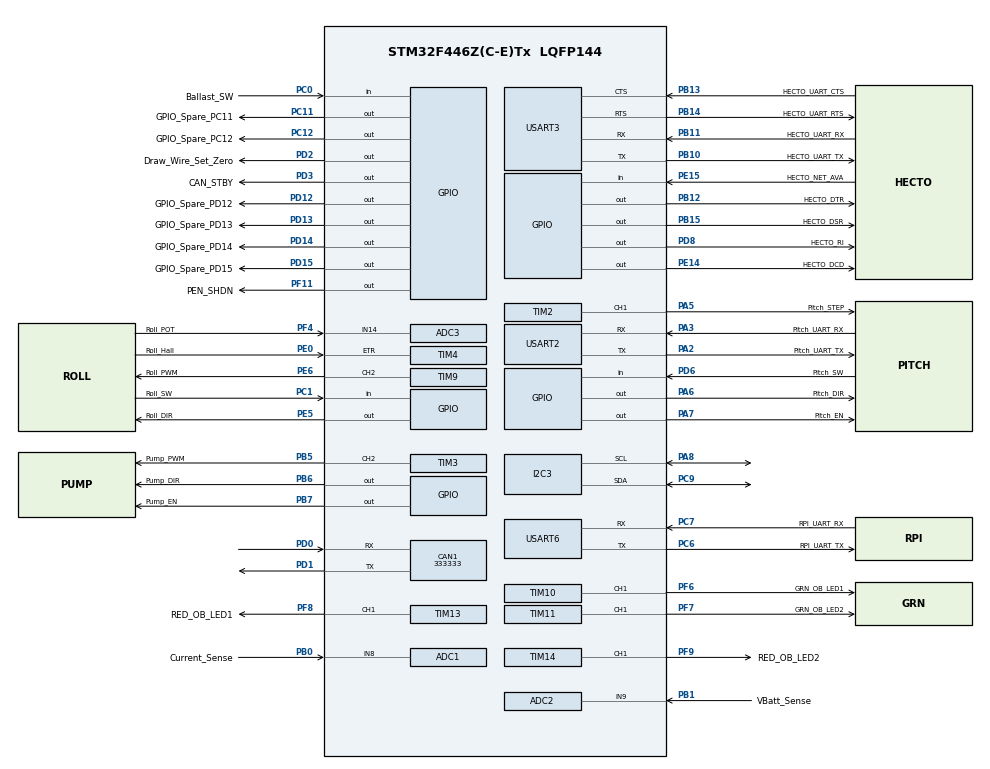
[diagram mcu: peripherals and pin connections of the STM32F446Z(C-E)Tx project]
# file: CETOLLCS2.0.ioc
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ADC1.Channel-0\#ChannelRegularConversion=ADC_CHANNEL_8
ADC1.NbrOfConversionFlag=1
ADC1.Rank-0\#ChannelRegularConversion=1
ADC1.SamplingTime-0\#ChannelRegularConversion=ADC_SAMPLETIME_3CYCLES
ADC1.master=1
ADC2.Channel-0\#ChannelRegularConversion=ADC_CHANNEL_9
ADC2.NbrOfConversionFlag=1
ADC2.Rank-0\#ChannelRegularConversion=1
ADC2.SamplingTime-0\#ChannelRegularConversion=ADC_SAMPLETIME_3CYCLES
ADC3.Channel-0\#ChannelRegularConversion=ADC_CHANNEL_14
ADC3.ContinuousConvMode=ENABLE
ADC3.DMAContinuousRequests=ENABLE
ADC3.NbrOfConversionFlag=1
ADC3.Rank-0\#ChannelRegularConversion=1
ADC3.SamplingTime-0\#ChannelRegularConversion=ADC_SAMPLETIME_3CYCLES
CAN1.CalculateBaudRate=333333
CAN1.CalculateTimeBit=3000
CAN1.CalculateTimeQuantum=1000.0
Dma.ADC3.0.Direction=DMA_PERIPH_TO_MEMORY
Dma.ADC3.0.FIFOMode=DMA_FIFOMODE_DISABLE
Dma.ADC3.0.Instance=DMA2_Stream0
Dma.ADC3.0.MemDataAlignment=DMA_MDATAALIGN_HALFWORD
Dma.ADC3.0.MemInc=DMA_MINC_DISABLE
Dma.ADC3.0.Mode=DMA_CIRCULAR
Dma.ADC3.0.PeriphDataAlignment=DMA_PDATAALIGN_HALFWORD
Dma.ADC3.0.PeriphInc=DMA_PINC_DISABLE
Dma.ADC3.0.Priority=DMA_PRIORITY_LOW
Dma.Request0=ADC3
FREERTOS.Tasks01=defaultTask,0,128,StartDefaultTask,Default,NULL,Dynamic,NULL,NULL
Mcu.Family=STM32F4
Mcu.Name=STM32F446Z(C-E)Tx
Mcu.Package=LQFP144
NVIC.DMA2_Stream0_IRQn=true\:5\:0\:false\:false\:true\:true\:false\:true\:true
NVIC.PriorityGroup=NVIC_PRIORITYGROUP_4
NVIC.TIM1_UP_TIM10_IRQn=true\:15\:0\:false\:false\:true\:false\:false\:true\:true
NVIC.TIM2_IRQn=true\:5\:0\:false\:false\:true\:true\:true\:true\:true
NVIC.TimeBase=TIM1_UP_TIM10_IRQn
NVIC.TimeBaseIP=TIM1
PA13.Mode=Serial_Wire
PA13.Signal=SYS_JTMS-SWDIO
PA14.Mode=Serial_Wire
PA14.Signal=SYS_JTCK-SWCLK
PA2.GPIO_Label=Pitch_UART_TX
PA2.Mode=Asynchronous
PA2.Signal=USART2_TX
PA3.GPIO_Label=Pitch_UART_RX
PA3.Mode=Asynchronous
PA3.Signal=USART2_RX
PA5.GPIO_Label=Pitch_STEP
PA5.Signal=S_TIM2_CH1_ETR
PA6.GPIO_Label=Pitch_DIR
PA6.Signal=GPIO_Output
PA7.GPIO_Label=Pitch_EN
PA7.Signal=GPIO_Output
PA8.Mode=I2C
PA8.Signal=I2C3_SCL
PB0.GPIO_Label=Current_Sense
PB0.Signal=ADCx_IN8
PB1.GPIO_Label=VBatt_Sense
PB1.Signal=ADCx_IN9
PB10.GPIO_Label=HECTO_UART_TX
PB10.Mode=Asynchronous
PB10.Signal=USART3_TX
PB11.GPIO_Label=HECTO_UART_RX
PB11.Mode=Asynchronous
PB11.Signal=USART3_RX
PB12.GPIO_Label=HECTO_DTR
PB12.Signal=GPIO_Output
PB13.GPIO_Label=HECTO_UART_CTS
PB13.Mode=CTS_RTS
PB13.Signal=USART3_CTS
PB14.GPIO_Label=HECTO_UART_RTS
PB14.Mode=CTS_RTS
PB14.Signal=USART3_RTS
PB15.GPIO_Label=HECTO_DSR
PB15.Signal=GPIO_Output
PB3.Signal=SYS_JTDO-SWO
PB5.GPIO_Label=Pump_PWM
PB5.Signal=S_TIM3_CH2
PB6.GPIO_Label=Pump_DIR
PB6.Signal=GPIO_Output
PB7.GPIO_Label=Pump_EN
PB7.Signal=GPIO_Output
PC0.GPIO_Label=Ballast_SW
PC0.Signal=GPIO_Input
PC1.GPIO_Label=Roll_SW
PC1.Signal=GPIO_Input
PC11.GPIO_Label=GPIO_Spare_PC11
PC11.Signal=GPIO_Output
PC12.GPIO_Label=GPIO_Spare_PC12
PC12.Signal=GPIO_Output
PC6.GPIO_Label=RPI_UART_TX
PC6.Mode=Asynchronous
PC6.Signal=USART6_TX
PC7.GPIO_Label=RPI_UART_RX
PC7.Mode=Asynchronous
PC7.Signal=USART6_RX
PC9.Mode=I2C
PC9.Signal=I2C3_SDA
PD0.Mode=CAN_Activate
PD0.Signal=CAN1_RX
PD1.Mode=CAN_Activate
PD1.Signal=CAN1_TX
PD12.GPIO_Label=GPIO_Spare_PD12
PD12.Signal=GPIO_Output
PD13.GPIO_Label=GPIO_Spare_PD13
PD13.Signal=GPIO_Output
PD14.GPIO_Label=GPIO_Spare_PD14
PD14.Signal=GPIO_Output
PD15.GPIO_Label=GPIO_Spare_PD15
PD15.Signal=GPIO_Output
PD2.GPIO_Label=Draw_Wire_Set_Zero
PD2.Signal=GPIO_Output
PD3.GPIO_Label=CAN_STBY
PD3.Signal=GPIO_Output
PD6.GPIO_Label=Pitch_SW
PD6.GPIO_PuPd=GPIO_PULLUP
PD6.Signal=GPIO_Input
PD8.GPIO_Label=HECTO_RI
PD8.Signal=GPIO_Output
PE0.GPIO_Label=Roll_Hall
PE0.Signal=S_TIM4_ETR
PE14.GPIO_Label=HECTO_DCD
PE14.Signal=GPIO_Output
PE15.GPIO_Label=HECTO_NET_AVA
PE15.Signal=GPIO_Input
PE5.GPIO_Label=Roll_DIR
PE5.Signal=GPIO_Output
PE6.GPIO_Label=Roll_PWM
PE6.Signal=S_TIM9_CH2
PF11.GPIO_Label=PEN_SHDN
PF11.Signal=GPIO_Output
PF4.GPIO_Label=Roll_POT
PF4.Mode=IN14
PF4.Signal=ADC3_IN14
PF6.GPIO_Label=GRN_OB_LED1
PF6.Signal=S_TIM10_CH1
PF7.GPIO_Label=GRN_OB_LED2
PF7.Signal=S_TIM11_CH1
PF8.GPIO_Label=RED_OB_LED1
PF8.Signal=S_TIM13_CH1
PF9.GPIO_Label=RED_OB_LED2
PF9.Signal=S_TIM14_CH1
PH0-OSC_IN.Mode=HSE-External-Oscillator
PH0-OSC_IN.Signal=RCC_OSC_IN
PH1-OSC_OUT.Mode=HSE-External-Oscillator
PH1-OSC_OUT.Signal=RCC_OSC_OUT
ProjectManager.HeapSize=0x200
ProjectManager.StackSize=0x400
ProjectManager.TargetToolchain=STM32CubeIDE
RCC.CortexFreq_Value=16000000
RCC.HSE_VALUE=16000000
RCC.PLLSourceVirtual=RCC_PLLSOURCE_HSE
RCC.SYSCLKSource=RCC_SYSCLKSOURCE_HSE
RCC.USBFreq_Value=96000000
RCC.VCOOutputFreq_Value=192000000
SH.ADCx_IN8.0=ADC1_IN8,IN8
SH.ADCx_IN9.0=ADC2_IN9,IN9
SH.S_TIM10_CH1.0=TIM10_CH1,PWM Generation1 CH1
SH.S_TIM11_CH1.0=TIM11_CH1,PWM Generation1 CH1
SH.S_TIM13_CH1.0=TIM13_CH1,PWM Generation1 CH1
SH.S_TIM14_CH1.0=TIM14_CH1,PWM Generation1 CH1
SH.S_TIM2_CH1_ETR.0=TIM2_CH1,PWM Generation1 CH1
SH.S_TIM3_CH2.0=TIM3_CH2,PWM Generation2 CH2
SH.S_TIM4_ETR.0=TIM4_ETR,ClockSourceETR_Mode2
SH.S_TIM9_CH2.0=TIM9_CH2,PWM Generation2 CH2
TIM10.Channel=TIM_CHANNEL_1
TIM11.Channel=TIM_CHANNEL_1
TIM13.Channel=TIM_CHANNEL_1
TIM14.Channel=TIM_CHANNEL_1
TIM2.AutoReloadPreload=TIM_AUTORELOAD_PRELOAD_ENABLE
TIM2.Channel-PWM\ Generation1\ CH1=TIM_CHANNEL_1
TIM2.Period=6000
TIM3.Channel-PWM\ Generation2\ CH2=TIM_CHANNEL_2
TIM9.Channel-PWM\ Generation2\ CH2=TIM_CHANNEL_2
USART2.VirtualMode=VM_ASYNC
USART3.VirtualMode=VM_ASYNC
USART6.VirtualMode=VM_ASYNC
VP_FREERTOS_VS_CMSIS_V1.Mode=CMSIS_V1
VP_SYS_VS_tim1.Mode=TIM1
VP_TIM10_VS_ClockSourceINT.Mode=Enable_Timer
VP_TIM11_VS_ClockSourceINT.Mode=Enable_Timer
VP_TIM13_VS_ClockSourceINT.Mode=Enable_Timer
VP_TIM14_VS_ClockSourceINT.Mode=Enable_Timer
board=custom

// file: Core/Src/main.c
/* USER CODE BEGIN Header */
/**
  ******************************************************************************
  * @file           : main.c
  * @brief          : Main program body
  ******************************************************************************
  * @attention
  *
  * Copyright (c) 2026 STMicroelectronics.
  * All rights reserved.
  *
  * This software is licensed under terms that can be found in the LICENSE file
  * in the root directory of this software component.
  * If no LICENSE file comes with this software, it is provided AS-IS.
  *
  ******************************************************************************
  */
/* USER CODE END Header */
#include "main.h"
#include "cmsis_os.h"

/* USER CODE BEGIN Includes */
#include "pitch_motor.h"

/* USER CODE END Includes */

ADC_HandleTypeDef hadc1;
ADC_HandleTypeDef hadc2;
ADC_HandleTypeDef hadc3;
DMA_HandleTypeDef hdma_adc3;

CAN_HandleTypeDef hcan1;

I2C_HandleTypeDef hi2c3;

TIM_HandleTypeDef htim2;
TIM_HandleTypeDef htim3;
TIM_HandleTypeDef htim4;
TIM_HandleTypeDef htim9;
TIM_HandleTypeDef htim10;
TIM_HandleTypeDef htim11;
TIM_HandleTypeDef htim13;
TIM_HandleTypeDef htim14;

UART_HandleTypeDef huart2;
UART_HandleTypeDef huart3;
UART_HandleTypeDef huart6;

osThreadId defaultTaskHandle;

void SystemClock_Config(void);
static void MX_GPIO_Init(void);
static void MX_DMA_Init(void);
static void MX_ADC1_Init(void);
static void MX_ADC2_Init(void);
static void MX_ADC3_Init(void);
static void MX_CAN1_Init(void);
static void MX_I2C3_Init(void);
static void MX_TIM2_Init(void);
static void MX_TIM3_Init(void);
static void MX_TIM4_Init(void);
static void MX_TIM9_Init(void);
static void MX_TIM10_Init(void);
static void MX_TIM11_Init(void);
static void MX_TIM13_Init(void);
static void MX_TIM14_Init(void);
static void MX_USART2_UART_Init(void);
static void MX_USART3_UART_Init(void);
static void MX_USART6_UART_Init(void);
void StartDefaultTask(void const * argument);

int main(void)
{

  /* MCU Configuration--------------------------------------------------------*/

  /* Reset of all peripherals, Initializes the Flash interface and the Systick. */
  HAL_Init();

  /* Configure the system clock */
  SystemClock_Config();

  /* Initialize all configured peripherals */
  MX_GPIO_Init();
  MX_DMA_Init();
  MX_ADC1_Init();
  MX_ADC2_Init();
  MX_ADC3_Init();
  MX_CAN1_Init();
  MX_I2C3_Init();
  MX_TIM2_Init();
  MX_TIM3_Init();
  MX_TIM4_Init();
  MX_TIM9_Init();
  MX_TIM10_Init();
  MX_TIM11_Init();
  MX_TIM13_Init();
  MX_TIM14_Init();
  MX_USART2_UART_Init();
  MX_USART3_UART_Init();
  MX_USART6_UART_Init();
  /* USER CODE BEGIN 2 */
  pitch_init_motor();
  HAL_Delay(50);

  while(1){
	  HAL_Delay(10);
	  pitch_move_to(90);

	  HAL_Delay(5);
	  pitch_move_to(10);
	  HAL_Delay(5);
  }
  /* USER CODE END 2 */

  /* Create the thread(s) */
  /* definition and creation of defaultTask */
  osThreadDef(defaultTask, StartDefaultTask, osPriorityNormal, 0, 128);
  defaultTaskHandle = osThreadCreate(osThread(defaultTask), NULL);

  /* Start scheduler */
  osKernelStart();

  /* We should never get here as control is now taken by the scheduler */

  /* Infinite loop */
  while (1)
  {

  }
}

void SystemClock_Config(void)
{
  RCC_OscInitTypeDef RCC_OscInitStruct = {0};
  RCC_ClkInitTypeDef RCC_ClkInitStruct = {0};

  /** Configure the main internal regulator output voltage
  */
  __HAL_RCC_PWR_CLK_ENABLE();
  __HAL_PWR_VOLTAGESCALING_CONFIG(PWR_REGULATOR_VOLTAGE_SCALE3);

  /** Initializes the RCC Oscillators according to the specified parameters
  * in the RCC_OscInitTypeDef structure.
  */
  RCC_OscInitStruct.OscillatorType = RCC_OSCILLATORTYPE_HSE;
  RCC_OscInitStruct.HSEState = RCC_HSE_ON;
  RCC_OscInitStruct.PLL.PLLState = RCC_PLL_NONE;
  if (HAL_RCC_OscConfig(&RCC_OscInitStruct) != HAL_OK)
  {
    Error_Handler();
  }

  /** Initializes the CPU, AHB and APB buses clocks
  */
  RCC_ClkInitStruct.ClockType = RCC_CLOCKTYPE_HCLK|RCC_CLOCKTYPE_SYSCLK
                              |RCC_CLOCKTYPE_PCLK1|RCC_CLOCKTYPE_PCLK2;
  RCC_ClkInitStruct.SYSCLKSource = RCC_SYSCLKSOURCE_HSE;
  RCC_ClkInitStruct.AHBCLKDivider = RCC_SYSCLK_DIV1;
  RCC_ClkInitStruct.APB1CLKDivider = RCC_HCLK_DIV1;
  RCC_ClkInitStruct.APB2CLKDivider = RCC_HCLK_DIV1;

  if (HAL_RCC_ClockConfig(&RCC_ClkInitStruct, FLASH_LATENCY_0) != HAL_OK)
  {
    Error_Handler();
  }
}

static void MX_ADC1_Init(void)
{

  ADC_ChannelConfTypeDef sConfig = {0};

  /** Configure the global features of the ADC (Clock, Resolution, Data Alignment and number of conversion)
  */
  hadc1.Instance = ADC1;
  hadc1.Init.ClockPrescaler = ADC_CLOCK_SYNC_PCLK_DIV2;
  hadc1.Init.Resolution = ADC_RESOLUTION_12B;
  hadc1.Init.ScanConvMode = DISABLE;
  hadc1.Init.ContinuousConvMode = DISABLE;
  hadc1.Init.DiscontinuousConvMode = DISABLE;
  hadc1.Init.ExternalTrigConvEdge = ADC_EXTERNALTRIGCONVEDGE_NONE;
  hadc1.Init.ExternalTrigConv = ADC_SOFTWARE_START;
  hadc1.Init.DataAlign = ADC_DATAALIGN_RIGHT;
  hadc1.Init.NbrOfConversion = 1;
  hadc1.Init.DMAContinuousRequests = DISABLE;
  hadc1.Init.EOCSelection = ADC_EOC_SINGLE_CONV;
  if (HAL_ADC_Init(&hadc1) != HAL_OK)
  {
    Error_Handler();
  }

  /** Configure for the selected ADC regular channel its corresponding rank in the sequencer and its sample time.
  */
  sConfig.Channel = ADC_CHANNEL_8;
  sConfig.Rank = 1;
  sConfig.SamplingTime = ADC_SAMPLETIME_3CYCLES;
  if (HAL_ADC_ConfigChannel(&hadc1, &sConfig) != HAL_OK)
  {
    Error_Handler();
  }

}

static void MX_ADC2_Init(void)
{

  ADC_ChannelConfTypeDef sConfig = {0};

  /** Configure the global features of the ADC (Clock, Resolution, Data Alignment and number of conversion)
  */
  hadc2.Instance = ADC2;
  hadc2.Init.ClockPrescaler = ADC_CLOCK_SYNC_PCLK_DIV2;
  hadc2.Init.Resolution = ADC_RESOLUTION_12B;
  hadc2.Init.ScanConvMode = DISABLE;
  hadc2.Init.ContinuousConvMode = DISABLE;
  hadc2.Init.DiscontinuousConvMode = DISABLE;
  hadc2.Init.ExternalTrigConvEdge = ADC_EXTERNALTRIGCONVEDGE_NONE;
  hadc2.Init.ExternalTrigConv = ADC_SOFTWARE_START;
  hadc2.Init.DataAlign = ADC_DATAALIGN_RIGHT;
  hadc2.Init.NbrOfConversion = 1;
  hadc2.Init.DMAContinuousRequests = DISABLE;
  hadc2.Init.EOCSelection = ADC_EOC_SINGLE_CONV;
  if (HAL_ADC_Init(&hadc2) != HAL_OK)
  {
    Error_Handler();
  }

  /** Configure for the selected ADC regular channel its corresponding rank in the sequencer and its sample time.
  */
  sConfig.Channel = ADC_CHANNEL_9;
  sConfig.Rank = 1;
  sConfig.SamplingTime = ADC_SAMPLETIME_3CYCLES;
  if (HAL_ADC_ConfigChannel(&hadc2, &sConfig) != HAL_OK)
  {
    Error_Handler();
  }

}

static void MX_ADC3_Init(void)
{

  ADC_ChannelConfTypeDef sConfig = {0};

  /** Configure the global features of the ADC (Clock, Resolution, Data Alignment and number of conversion)
  */
  hadc3.Instance = ADC3;
  hadc3.Init.ClockPrescaler = ADC_CLOCK_SYNC_PCLK_DIV2;
  hadc3.Init.Resolution = ADC_RESOLUTION_12B;
  hadc3.Init.ScanConvMode = DISABLE;
  hadc3.Init.ContinuousConvMode = ENABLE;
  hadc3.Init.DiscontinuousConvMode = DISABLE;
  hadc3.Init.ExternalTrigConvEdge = ADC_EXTERNALTRIGCONVEDGE_NONE;
  hadc3.Init.ExternalTrigConv = ADC_SOFTWARE_START;
  hadc3.Init.DataAlign = ADC_DATAALIGN_RIGHT;
  hadc3.Init.NbrOfConversion = 1;
  hadc3.Init.DMAContinuousRequests = ENABLE;
  hadc3.Init.EOCSelection = ADC_EOC_SINGLE_CONV;
  if (HAL_ADC_Init(&hadc3) != HAL_OK)
  {
    Error_Handler();
  }

  /** Configure for the selected ADC regular channel its corresponding rank in the sequencer and its sample time.
  */
  sConfig.Channel = ADC_CHANNEL_14;
  sConfig.Rank = 1;
  sConfig.SamplingTime = ADC_SAMPLETIME_3CYCLES;
  if (HAL_ADC_ConfigChannel(&hadc3, &sConfig) != HAL_OK)
  {
    Error_Handler();
  }

}

static void MX_CAN1_Init(void)
{

  hcan1.Instance = CAN1;
  hcan1.Init.Prescaler = 16;
  hcan1.Init.Mode = CAN_MODE_NORMAL;
  hcan1.Init.SyncJumpWidth = CAN_SJW_1TQ;
  hcan1.Init.TimeSeg1 = CAN_BS1_1TQ;
  hcan1.Init.TimeSeg2 = CAN_BS2_1TQ;
  hcan1.Init.TimeTriggeredMode = DISABLE;
  hcan1.Init.AutoBusOff = DISABLE;
  hcan1.Init.AutoWakeUp = DISABLE;
  hcan1.Init.AutoRetransmission = DISABLE;
  hcan1.Init.ReceiveFifoLocked = DISABLE;
  hcan1.Init.TransmitFifoPriority = DISABLE;
  if (HAL_CAN_Init(&hcan1) != HAL_OK)
  {
    Error_Handler();
  }

}

static void MX_I2C3_Init(void)
{

  hi2c3.Instance = I2C3;
  hi2c3.Init.ClockSpeed = 100000;
  hi2c3.Init.DutyCycle = I2C_DUTYCYCLE_2;
  hi2c3.Init.OwnAddress1 = 0;
  hi2c3.Init.AddressingMode = I2C_ADDRESSINGMODE_7BIT;
  hi2c3.Init.DualAddressMode = I2C_DUALADDRESS_DISABLE;
  hi2c3.Init.OwnAddress2 = 0;
  hi2c3.Init.GeneralCallMode = I2C_GENERALCALL_DISABLE;
  hi2c3.Init.NoStretchMode = I2C_NOSTRETCH_DISABLE;
  if (HAL_I2C_Init(&hi2c3) != HAL_OK)
  {
    Error_Handler();
  }

}

static void MX_TIM2_Init(void)
{

  TIM_MasterConfigTypeDef sMasterConfig = {0};
  TIM_OC_InitTypeDef sConfigOC = {0};

  htim2.Instance = TIM2;
  htim2.Init.Prescaler = 0;
  htim2.Init.CounterMode = TIM_COUNTERMODE_UP;
  htim2.Init.Period = 6000;
  htim2.Init.ClockDivision = TIM_CLOCKDIVISION_DIV1;
  htim2.Init.AutoReloadPreload = TIM_AUTORELOAD_PRELOAD_ENABLE;
  if (HAL_TIM_PWM_Init(&htim2) != HAL_OK)
  {
    Error_Handler();
  }
  sMasterConfig.MasterOutputTrigger = TIM_TRGO_RESET;
  sMasterConfig.MasterSlaveMode = TIM_MASTERSLAVEMODE_DISABLE;
  if (HAL_TIMEx_MasterConfigSynchronization(&htim2, &sMasterConfig) != HAL_OK)
  {
    Error_Handler();
  }
  sConfigOC.OCMode = TIM_OCMODE_PWM1;
  sConfigOC.Pulse = 0;
  sConfigOC.OCPolarity = TIM_OCPOLARITY_HIGH;
  sConfigOC.OCFastMode = TIM_OCFAST_DISABLE;
  if (HAL_TIM_PWM_ConfigChannel(&htim2, &sConfigOC, TIM_CHANNEL_1) != HAL_OK)
  {
    Error_Handler();
  }
  HAL_TIM_MspPostInit(&htim2);

}

static void MX_TIM3_Init(void)
{

  TIM_MasterConfigTypeDef sMasterConfig = {0};
  TIM_OC_InitTypeDef sConfigOC = {0};

  htim3.Instance = TIM3;
  htim3.Init.Prescaler = 0;
  htim3.Init.CounterMode = TIM_COUNTERMODE_UP;
  htim3.Init.Period = 65535;
  htim3.Init.ClockDivision = TIM_CLOCKDIVISION_DIV1;
  htim3.Init.AutoReloadPreload = TIM_AUTORELOAD_PRELOAD_DISABLE;
  if (HAL_TIM_PWM_Init(&htim3) != HAL_OK)
  {
    Error_Handler();
  }
  sMasterConfig.MasterOutputTrigger = TIM_TRGO_RESET;
  sMasterConfig.MasterSlaveMode = TIM_MASTERSLAVEMODE_DISABLE;
  if (HAL_TIMEx_MasterConfigSynchronization(&htim3, &sMasterConfig) != HAL_OK)
  {
    Error_Handler();
  }
  sConfigOC.OCMode = TIM_OCMODE_PWM1;
  sConfigOC.Pulse = 0;
  sConfigOC.OCPolarity = TIM_OCPOLARITY_HIGH;
  sConfigOC.OCFastMode = TIM_OCFAST_DISABLE;
  if (HAL_TIM_PWM_ConfigChannel(&htim3, &sConfigOC, TIM_CHANNEL_2) != HAL_OK)
  {
    Error_Handler();
  }
  HAL_TIM_MspPostInit(&htim3);

}

static void MX_TIM4_Init(void)
{

  TIM_ClockConfigTypeDef sClockSourceConfig = {0};
  TIM_MasterConfigTypeDef sMasterConfig = {0};

  htim4.Instance = TIM4;
  htim4.Init.Prescaler = 0;
  htim4.Init.CounterMode = TIM_COUNTERMODE_UP;
  htim4.Init.Period = 65535;
  htim4.Init.ClockDivision = TIM_CLOCKDIVISION_DIV1;
  htim4.Init.AutoReloadPreload = TIM_AUTORELOAD_PRELOAD_DISABLE;
  if (HAL_TIM_Base_Init(&htim4) != HAL_OK)
  {
    Error_Handler();
  }
  sClockSourceConfig.ClockSource = TIM_CLOCKSOURCE_ETRMODE2;
  sClockSourceConfig.ClockPolarity = TIM_CLOCKPOLARITY_NONINVERTED;
  sClockSourceConfig.ClockPrescaler = TIM_CLOCKPRESCALER_DIV1;
  sClockSourceConfig.ClockFilter = 0;
  if (HAL_TIM_ConfigClockSource(&htim4, &sClockSourceConfig) != HAL_OK)
  {
    Error_Handler();
  }
  sMasterConfig.MasterOutputTrigger = TIM_TRGO_RESET;
  sMasterConfig.MasterSlaveMode = TIM_MASTERSLAVEMODE_DISABLE;
  if (HAL_TIMEx_MasterConfigSynchronization(&htim4, &sMasterConfig) != HAL_OK)
  {
    Error_Handler();
  }

}

static void MX_TIM9_Init(void)
{

  TIM_OC_InitTypeDef sConfigOC = {0};

  htim9.Instance = TIM9;
  htim9.Init.Prescaler = 0;
  htim9.Init.CounterMode = TIM_COUNTERMODE_UP;
  htim9.Init.Period = 65535;
  htim9.Init.ClockDivision = TIM_CLOCKDIVISION_DIV1;
  htim9.Init.AutoReloadPreload = TIM_AUTORELOAD_PRELOAD_DISABLE;
  if (HAL_TIM_PWM_Init(&htim9) != HAL_OK)
  {
    Error_Handler();
  }
  sConfigOC.OCMode = TIM_OCMODE_PWM1;
  sConfigOC.Pulse = 0;
  sConfigOC.OCPolarity = TIM_OCPOLARITY_HIGH;
  sConfigOC.OCFastMode = TIM_OCFAST_DISABLE;
  if (HAL_TIM_PWM_ConfigChannel(&htim9, &sConfigOC, TIM_CHANNEL_2) != HAL_OK)
  {
    Error_Handler();
  }
  HAL_TIM_MspPostInit(&htim9);

}

static void MX_TIM10_Init(void)
{

  TIM_OC_InitTypeDef sConfigOC = {0};

  htim10.Instance = TIM10;
  htim10.Init.Prescaler = 0;
  htim10.Init.CounterMode = TIM_COUNTERMODE_UP;
  htim10.Init.Period = 65535;
  htim10.Init.ClockDivision = TIM_CLOCKDIVISION_DIV1;
  htim10.Init.AutoReloadPreload = TIM_AUTORELOAD_PRELOAD_DISABLE;
  if (HAL_TIM_Base_Init(&htim10) != HAL_OK)
  {
    Error_Handler();
  }
  if (HAL_TIM_PWM_Init(&htim10) != HAL_OK)
  {
    Error_Handler();
  }
  sConfigOC.OCMode = TIM_OCMODE_PWM1;
  sConfigOC.Pulse = 0;
  sConfigOC.OCPolarity = TIM_OCPOLARITY_HIGH;
  sConfigOC.OCFastMode = TIM_OCFAST_DISABLE;
  if (HAL_TIM_PWM_ConfigChannel(&htim10, &sConfigOC, TIM_CHANNEL_1) != HAL_OK)
  {
    Error_Handler();
  }
  HAL_TIM_MspPostInit(&htim10);

}

static void MX_TIM11_Init(void)
{

  TIM_OC_InitTypeDef sConfigOC = {0};

  htim11.Instance = TIM11;
  htim11.Init.Prescaler = 0;
  htim11.Init.CounterMode = TIM_COUNTERMODE_UP;
  htim11.Init.Period = 65535;
  htim11.Init.ClockDivision = TIM_CLOCKDIVISION_DIV1;
  htim11.Init.AutoReloadPreload = TIM_AUTORELOAD_PRELOAD_DISABLE;
  if (HAL_TIM_Base_Init(&htim11) != HAL_OK)
  {
    Error_Handler();
  }
  if (HAL_TIM_PWM_Init(&htim11) != HAL_OK)
  {
    Error_Handler();
  }
  sConfigOC.OCMode = TIM_OCMODE_PWM1;
  sConfigOC.Pulse = 0;
  sConfigOC.OCPolarity = TIM_OCPOLARITY_HIGH;
  sConfigOC.OCFastMode = TIM_OCFAST_DISABLE;
  if (HAL_TIM_PWM_ConfigChannel(&htim11, &sConfigOC, TIM_CHANNEL_1) != HAL_OK)
  {
    Error_Handler();
  }
  HAL_TIM_MspPostInit(&htim11);

}

static void MX_TIM13_Init(void)
{

  TIM_OC_InitTypeDef sConfigOC = {0};

  htim13.Instance = TIM13;
  htim13.Init.Prescaler = 0;
  htim13.Init.CounterMode = TIM_COUNTERMODE_UP;
  htim13.Init.Period = 65535;
  htim13.Init.ClockDivision = TIM_CLOCKDIVISION_DIV1;
  htim13.Init.AutoReloadPreload = TIM_AUTORELOAD_PRELOAD_DISABLE;
  if (HAL_TIM_Base_Init(&htim13) != HAL_OK)
  {
    Error_Handler();
  }
  if (HAL_TIM_PWM_Init(&htim13) != HAL_OK)
  {
    Error_Handler();
  }
  sConfigOC.OCMode = TIM_OCMODE_PWM1;
  sConfigOC.Pulse = 0;
  sConfigOC.OCPolarity = TIM_OCPOLARITY_HIGH;
  sConfigOC.OCFastMode = TIM_OCFAST_DISABLE;
  if (HAL_TIM_PWM_ConfigChannel(&htim13, &sConfigOC, TIM_CHANNEL_1) != HAL_OK)
  {
    Error_Handler();
  }
  HAL_TIM_MspPostInit(&htim13);

}

static void MX_TIM14_Init(void)
{

  TIM_OC_InitTypeDef sConfigOC = {0};

  htim14.Instance = TIM14;
  htim14.Init.Prescaler = 0;
  htim14.Init.CounterMode = TIM_COUNTERMODE_UP;
  htim14.Init.Period = 65535;
  htim14.Init.ClockDivision = TIM_CLOCKDIVISION_DIV1;
  htim14.Init.AutoReloadPreload = TIM_AUTORELOAD_PRELOAD_DISABLE;
  if (HAL_TIM_Base_Init(&htim14) != HAL_OK)
  {
    Error_Handler();
  }
  if (HAL_TIM_PWM_Init(&htim14) != HAL_OK)
  {
    Error_Handler();
  }
  sConfigOC.OCMode = TIM_OCMODE_PWM1;
  sConfigOC.Pulse = 0;
  sConfigOC.OCPolarity = TIM_OCPOLARITY_HIGH;
  sConfigOC.OCFastMode = TIM_OCFAST_DISABLE;
  if (HAL_TIM_PWM_ConfigChannel(&htim14, &sConfigOC, TIM_CHANNEL_1) != HAL_OK)
  {
    Error_Handler();
  }
  HAL_TIM_MspPostInit(&htim14);

}

static void MX_USART2_UART_Init(void)
{

  huart2.Instance = USART2;
  huart2.Init.BaudRate = 115200;
  huart2.Init.WordLength = UART_WORDLENGTH_8B;
  huart2.Init.StopBits = UART_STOPBITS_1;
  huart2.Init.Parity = UART_PARITY_NONE;
  huart2.Init.Mode = UART_MODE_TX_RX;
  huart2.Init.HwFlowCtl = UART_HWCONTROL_NONE;
  huart2.Init.OverSampling = UART_OVERSAMPLING_16;
  if (HAL_UART_Init(&huart2) != HAL_OK)
  {
    Error_Handler();
  }

}

static void MX_USART3_UART_Init(void)
{

  huart3.Instance = USART3;
  huart3.Init.BaudRate = 115200;
  huart3.Init.WordLength = UART_WORDLENGTH_8B;
  huart3.Init.StopBits = UART_STOPBITS_1;
  huart3.Init.Parity = UART_PARITY_NONE;
  huart3.Init.Mode = UART_MODE_TX_RX;
  huart3.Init.HwFlowCtl = UART_HWCONTROL_RTS_CTS;
  huart3.Init.OverSampling = UART_OVERSAMPLING_16;
  if (HAL_UART_Init(&huart3) != HAL_OK)
  {
    Error_Handler();
  }

}

static void MX_USART6_UART_Init(void)
{

  huart6.Instance = USART6;
  huart6.Init.BaudRate = 115200;
  huart6.Init.WordLength = UART_WORDLENGTH_8B;
  huart6.Init.StopBits = UART_STOPBITS_1;
  huart6.Init.Parity = UART_PARITY_NONE;
  huart6.Init.Mode = UART_MODE_TX_RX;
  huart6.Init.HwFlowCtl = UART_HWCONTROL_NONE;
  huart6.Init.OverSampling = UART_OVERSAMPLING_16;
  if (HAL_UART_Init(&huart6) != HAL_OK)
  {
    Error_Handler();
  }

}

static void MX_DMA_Init(void)
{

  /* DMA controller clock enable */
  __HAL_RCC_DMA2_CLK_ENABLE();

  /* DMA interrupt init */
  /* DMA2_Stream0_IRQn interrupt configuration */
  HAL_NVIC_SetPriority(DMA2_Stream0_IRQn, 5, 0);
  HAL_NVIC_EnableIRQ(DMA2_Stream0_IRQn);

}

static void MX_GPIO_Init(void)
{
  GPIO_InitTypeDef GPIO_InitStruct = {0};

  /* GPIO Ports Clock Enable */
  __HAL_RCC_GPIOE_CLK_ENABLE();
  __HAL_RCC_GPIOC_CLK_ENABLE();
  __HAL_RCC_GPIOF_CLK_ENABLE();
  __HAL_RCC_GPIOH_CLK_ENABLE();
  __HAL_RCC_GPIOA_CLK_ENABLE();
  __HAL_RCC_GPIOB_CLK_ENABLE();
  __HAL_RCC_GPIOG_CLK_ENABLE();
  __HAL_RCC_GPIOD_CLK_ENABLE();

  /*Configure GPIO pin Output Level */
  HAL_GPIO_WritePin(GPIOE, Roll_DIR_Pin|HECTO_DCD_Pin, GPIO_PIN_RESET);

  /*Configure GPIO pin Output Level */
  HAL_GPIO_WritePin(GPIOA, Pitch_DIR_Pin|Pitch_EN_Pin, GPIO_PIN_RESET);

  /*Configure GPIO pin Output Level */
  HAL_GPIO_WritePin(PEN_SHDN_GPIO_Port, PEN_SHDN_Pin, GPIO_PIN_RESET);

  /*Configure GPIO pin Output Level */
  HAL_GPIO_WritePin(GPIOB, HECTO_DTR_Pin|HECTO_DSR_Pin|Pump_DIR_Pin|Pump_EN_Pin, GPIO_PIN_RESET);

  /*Configure GPIO pin Output Level */
  HAL_GPIO_WritePin(GPIOD, HECTO_RI_Pin|GPIO_Spare_PD12_Pin|GPIO_Spare_PD13_Pin|GPIO_Spare_PD14_Pin
                          |GPIO_Spare_PD15_Pin|Draw_Wire_Set_Zero_Pin|CAN_STBY_Pin, GPIO_PIN_RESET);

  /*Configure GPIO pin Output Level */
  HAL_GPIO_WritePin(GPIOC, GPIO_Spare_PC11_Pin|GPIO_Spare_PC12_Pin, GPIO_PIN_RESET);

  /*Configure GPIO pins : PE2 PE3 PE4 PE7
                           PE8 PE9 PE10 PE11
                           PE12 PE13 PE1 */
  GPIO_InitStruct.Pin = GPIO_PIN_2|GPIO_PIN_3|GPIO_PIN_4|GPIO_PIN_7
                          |GPIO_PIN_8|GPIO_PIN_9|GPIO_PIN_10|GPIO_PIN_11
                          |GPIO_PIN_12|GPIO_PIN_13|GPIO_PIN_1;
  GPIO_InitStruct.Mode = GPIO_MODE_ANALOG;
  GPIO_InitStruct.Pull = GPIO_NOPULL;
  HAL_GPIO_Init(GPIOE, &GPIO_InitStruct);

  /*Configure GPIO pins : Roll_DIR_Pin HECTO_DCD_Pin */
  GPIO_InitStruct.Pin = Roll_DIR_Pin|HECTO_DCD_Pin;
  GPIO_InitStruct.Mode = GPIO_MODE_OUTPUT_PP;
  GPIO_InitStruct.Pull = GPIO_NOPULL;
  GPIO_InitStruct.Speed = GPIO_SPEED_FREQ_LOW;
  HAL_GPIO_Init(GPIOE, &GPIO_InitStruct);

  /*Configure GPIO pins : PC13 PC14 PC15 PC2
                           PC3 PC4 PC5 PC8
                           PC10 */
  GPIO_InitStruct.Pin = GPIO_PIN_13|GPIO_PIN_14|GPIO_PIN_15|GPIO_PIN_2
                          |GPIO_PIN_3|GPIO_PIN_4|GPIO_PIN_5|GPIO_PIN_8
                          |GPIO_PIN_10;
  GPIO_InitStruct.Mode = GPIO_MODE_ANALOG;
  GPIO_InitStruct.Pull = GPIO_NOPULL;
  HAL_GPIO_Init(GPIOC, &GPIO_InitStruct);

  /*Configure GPIO pins : PF0 PF1 PF2 PF3
                           PF5 PF10 PF12 PF13
                           PF14 PF15 */
  GPIO_InitStruct.Pin = GPIO_PIN_0|GPIO_PIN_1|GPIO_PIN_2|GPIO_PIN_3
                          |GPIO_PIN_5|GPIO_PIN_10|GPIO_PIN_12|GPIO_PIN_13
                          |GPIO_PIN_14|GPIO_PIN_15;
  GPIO_InitStruct.Mode = GPIO_MODE_ANALOG;
  GPIO_InitStruct.Pull = GPIO_NOPULL;
  HAL_GPIO_Init(GPIOF, &GPIO_InitStruct);

  /*Configure GPIO pins : Ballast_SW_Pin Roll_SW_Pin */
  GPIO_InitStruct.Pin = Ballast_SW_Pin|Roll_SW_Pin;
  GPIO_InitStruct.Mode = GPIO_MODE_INPUT;
  GPIO_InitStruct.Pull = GPIO_NOPULL;
  HAL_GPIO_Init(GPIOC, &GPIO_InitStruct);

  /*Configure GPIO pins : PA0 PA1 PA4 PA9
                           PA10 PA11 PA12 PA15 */
  GPIO_InitStruct.Pin = GPIO_PIN_0|GPIO_PIN_1|GPIO_PIN_4|GPIO_PIN_9
                          |GPIO_PIN_10|GPIO_PIN_11|GPIO_PIN_12|GPIO_PIN_15;
  GPIO_InitStruct.Mode = GPIO_MODE_ANALOG;
  GPIO_InitStruct.Pull = GPIO_NOPULL;
  HAL_GPIO_Init(GPIOA, &GPIO_InitStruct);

  /*Configure GPIO pins : Pitch_DIR_Pin Pitch_EN_Pin */
  GPIO_InitStruct.Pin = Pitch_DIR_Pin|Pitch_EN_Pin;
  GPIO_InitStruct.Mode = GPIO_MODE_OUTPUT_PP;
  GPIO_InitStruct.Pull = GPIO_NOPULL;
  GPIO_InitStruct.Speed = GPIO_SPEED_FREQ_LOW;
  HAL_GPIO_Init(GPIOA, &GPIO_InitStruct);

  /*Configure GPIO pins : PB2 PB4 PB8 PB9 */
  GPIO_InitStruct.Pin = GPIO_PIN_2|GPIO_PIN_4|GPIO_PIN_8|GPIO_PIN_9;
  GPIO_InitStruct.Mode = GPIO_MODE_ANALOG;
  GPIO_InitStruct.Pull = GPIO_NOPULL;
  HAL_GPIO_Init(GPIOB, &GPIO_InitStruct);

  /*Configure GPIO pin : PEN_SHDN_Pin */
  GPIO_InitStruct.Pin = PEN_SHDN_Pin;
  GPIO_InitStruct.Mode = GPIO_MODE_OUTPUT_PP;
  GPIO_InitStruct.Pull = GPIO_NOPULL;
  GPIO_InitStruct.Speed = GPIO_SPEED_FREQ_LOW;
  HAL_GPIO_Init(PEN_SHDN_GPIO_Port, &GPIO_InitStruct);

  /*Configure GPIO pins : PG0 PG1 PG2 PG3
                           PG4 PG5 PG6 PG7
                           PG8 PG9 PG10 PG11
                           PG12 PG13 PG14 PG15 */
  GPIO_InitStruct.Pin = GPIO_PIN_0|GPIO_PIN_1|GPIO_PIN_2|GPIO_PIN_3
                          |GPIO_PIN_4|GPIO_PIN_5|GPIO_PIN_6|GPIO_PIN_7
                          |GPIO_PIN_8|GPIO_PIN_9|GPIO_PIN_10|GPIO_PIN_11
                          |GPIO_PIN_12|GPIO_PIN_13|GPIO_PIN_14|GPIO_PIN_15;
  GPIO_InitStruct.Mode = GPIO_MODE_ANALOG;
  GPIO_InitStruct.Pull = GPIO_NOPULL;
  HAL_GPIO_Init(GPIOG, &GPIO_InitStruct);

  /*Configure GPIO pin : HECTO_NET_AVA_Pin */
  GPIO_InitStruct.Pin = HECTO_NET_AVA_Pin;
  GPIO_InitStruct.Mode = GPIO_MODE_INPUT;
  GPIO_InitStruct.Pull = GPIO_NOPULL;
  HAL_GPIO_Init(HECTO_NET_AVA_GPIO_Port, &GPIO_InitStruct);

  /*Configure GPIO pins : HECTO_DTR_Pin HECTO_DSR_Pin Pump_DIR_Pin Pump_EN_Pin */
  GPIO_InitStruct.Pin = HECTO_DTR_Pin|HECTO_DSR_Pin|Pump_DIR_Pin|Pump_EN_Pin;
  GPIO_InitStruct.Mode = GPIO_MODE_OUTPUT_PP;
  GPIO_InitStruct.Pull = GPIO_NOPULL;
  GPIO_InitStruct.Speed = GPIO_SPEED_FREQ_LOW;
  HAL_GPIO_Init(GPIOB, &GPIO_InitStruct);

  /*Configure GPIO pins : HECTO_RI_Pin GPIO_Spare_PD12_Pin GPIO_Spare_PD13_Pin GPIO_Spare_PD14_Pin
                           GPIO_Spare_PD15_Pin Draw_Wire_Set_Zero_Pin CAN_STBY_Pin */
  GPIO_InitStruct.Pin = HECTO_RI_Pin|GPIO_Spare_PD12_Pin|GPIO_Spare_PD13_Pin|GPIO_Spare_PD14_Pin
                          |GPIO_Spare_PD15_Pin|Draw_Wire_Set_Zero_Pin|CAN_STBY_Pin;
  GPIO_InitStruct.Mode = GPIO_MODE_OUTPUT_PP;
  GPIO_InitStruct.Pull = GPIO_NOPULL;
  GPIO_InitStruct.Speed = GPIO_SPEED_FREQ_LOW;
  HAL_GPIO_Init(GPIOD, &GPIO_InitStruct);

  /*Configure GPIO pins : PD9 PD10 PD11 PD4
                           PD5 PD7 */
  GPIO_InitStruct.Pin = GPIO_PIN_9|GPIO_PIN_10|GPIO_PIN_11|GPIO_PIN_4
                          |GPIO_PIN_5|GPIO_PIN_7;
  GPIO_InitStruct.Mode = GPIO_MODE_ANALOG;
  GPIO_InitStruct.Pull = GPIO_NOPULL;
  HAL_GPIO_Init(GPIOD, &GPIO_InitStruct);

  /*Configure GPIO pins : GPIO_Spare_PC11_Pin GPIO_Spare_PC12_Pin */
  GPIO_InitStruct.Pin = GPIO_Spare_PC11_Pin|GPIO_Spare_PC12_Pin;
  GPIO_InitStruct.Mode = GPIO_MODE_OUTPUT_PP;
  GPIO_InitStruct.Pull = GPIO_NOPULL;
  GPIO_InitStruct.Speed = GPIO_SPEED_FREQ_LOW;
  HAL_GPIO_Init(GPIOC, &GPIO_InitStruct);

  /*Configure GPIO pin : Pitch_SW_Pin */
  GPIO_InitStruct.Pin = Pitch_SW_Pin;
  GPIO_InitStruct.Mode = GPIO_MODE_INPUT;
  GPIO_InitStruct.Pull = GPIO_PULLUP;
  HAL_GPIO_Init(Pitch_SW_GPIO_Port, &GPIO_InitStruct);

}

/* USER CODE BEGIN 4 */
void HAL_TIM_PWM_PulseFinishedCallback(TIM_HandleTypeDef *htim)
{
    pitch_handle_pwm_pulse_finished(htim);
}
/* USER CODE END 4 */

void StartDefaultTask(void const * argument)
{
  for(;;)
  {
    osDelay(1);
  }
}

void HAL_TIM_PeriodElapsedCallback(TIM_HandleTypeDef *htim)
{
  if (htim->Instance == TIM1)
  {
    HAL_IncTick();
  }
}

void Error_Handler(void)
{
  __disable_irq();
  while (1)
  {
  }
}
